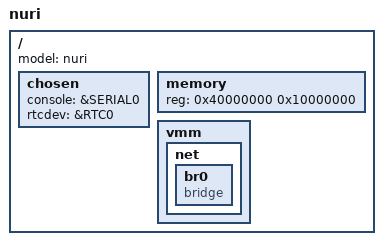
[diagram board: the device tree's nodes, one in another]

/include/ "../exynos4210.dtsi"

/ {
	model = "nuri";

	chosen {
		console = &SERIAL0;
		rtcdev = &RTC0;
	};

	memory {
		device_type = "memory"; 
		reg = <0x40000000 0x10000000>; /* 256 MB */
	};

	vmm {
		net {
			br0 {
				device_type = "netswitch";
				compatible = "bridge";
			};
		};
	};
};

/* Add guest templates */
/include/ "../../../common/guests/realview-pb-a8.dtsi"
/include/ "../../../common/guests/vexpress-a9x2.dtsi"

